# STM32U5G9 register map
File version: 1.3
CPU: CM33 r0p1, little endian, MPU, FPU, 4 interrupt priority bits
Registers are 32-bit, read-write, reset 0x0 unless marked. A register's access mark holds for its fields unless they carry their own. Offsets are from the block's base; [hi:lo] are bit positions; {n}, {i} and the like mark numbered series; 'fields as' and 'values as' point back to an identical list.

## DSI
Base 0x40016C00
Same registers: SEC_DSI 0x50016C00
0x00 DSI_VR ro reset 0x3134312A — DSI Host version register
  [31:0] VERSION — Version of the DSI Host
0x04 DSI_CR — DSI Host control register
  [0] EN — Enable
    0=DSI Host disabled (under reset); 1=DSI Host enabled
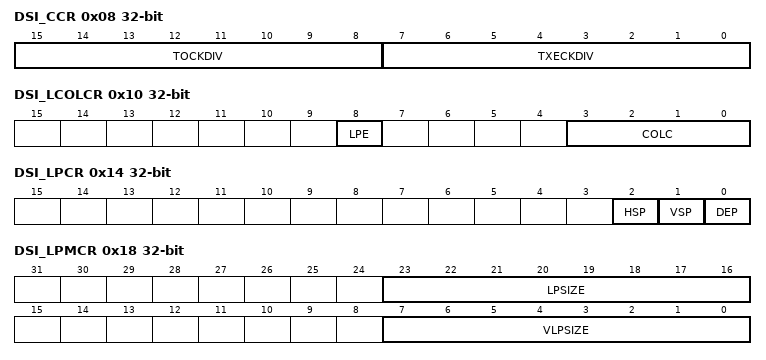
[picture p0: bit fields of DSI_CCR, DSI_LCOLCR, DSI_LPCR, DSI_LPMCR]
0x08 DSI_CCR — DSI Host clock control register
  [15:8] TOCKDIV — Timeout clock division
  [7:0] TXECKDIV — TX escape clock division
0x0C DSI_LVCIDR — DSI Host LTDC VCID register
  [1:0] VCID — Virtual channel ID
0x10 DSI_LCOLCR — DSI Host LTDC color coding register
  [8] LPE — Loosely packet enable
    0=Loosely packet variant disabled; 1=Loosely packet variant enabled
  [3:0] COLC — Color coding
    0=16-bit configuration 1; 1=16-bit configuration 2; 2=16-bit configuration 3; 3=18-bit configuration 1; 4=18-bit configuration 2; 5=24-bit
0x14 DSI_LPCR — DSI Host LTDC polarity configuration register
  [2] HSP — HSYNC polarity
    0=HSYNC pin active high (default); 1=VSYNC pin active low
  [1] VSP — VSYNC polarity
    0=Shutdown pin active high (default); 1=Shutdown pin active low
  [0] DEP — Data enable polarity
    0=Data enable pin active high (default); 1=Data enable pin active low
0x18 DSI_LPMCR — DSI Host low-power mode configuration register
  [23:16] LPSIZE — Largest packet size
  [7:0] VLPSIZE — VACT largest packet size
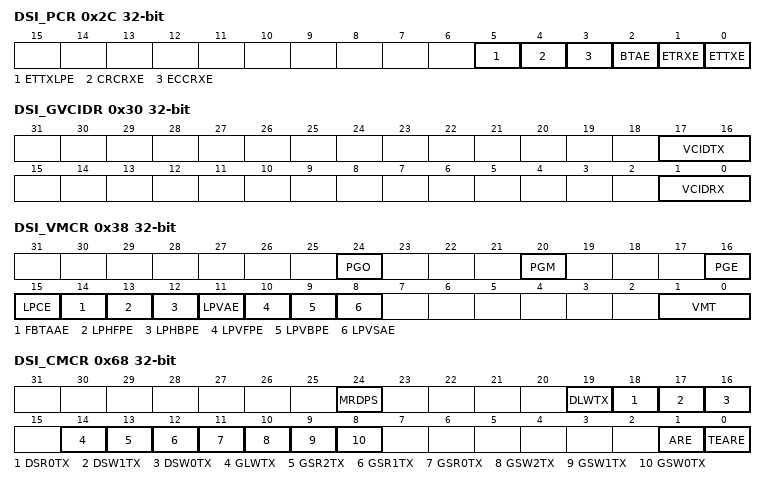
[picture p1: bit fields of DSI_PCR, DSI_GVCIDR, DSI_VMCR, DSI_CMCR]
0x2C DSI_PCR — DSI Host protocol configuration register
  [5] ETTXLPE — EoTp transmission in low-power enable
    0=EoTp transmission in low-power is disabled; 1=EoTp transmission in low-power is enabled
  [4] CRCRXE — CRC reception enable
    0=CRC reception is disabled; 1=CRC reception is enabled
  [3] ECCRXE — ECC reception enable
    0=ECC reception is disabled; 1=ECC reception is enabled
  [2] BTAE — Bus-turn-around enable
    0=Bus-turn-around request is disabled; 1=Bus-turn-around request is enabled
  [1] ETRXE — EoTp reception enable
    0=EoTp reception is disabled; 1=EoTp reception is enabled
  [0] ETTXE — EoTp transmission enable
    0=EoTp transmission is disabled; 1=EoTp transmission is enabled
0x30 DSI_GVCIDR — DSI Host generic VCID register
  [17:16] VCIDTX — Virtual channel ID for transmission
  [1:0] VCIDRX — Virtual channel ID for reception
0x34 DSI_MCR reset 0x1 — DSI Host mode configuration register
  [0] CMDM — Command mode
    0=DSI Host is configured in video mode; 1=DSI Host is configured in command mode
0x38 DSI_VMCR — DSI Host video mode configuration register
  [24] PGO — Pattern generator orientation
    0=Vertical color bars; 1=Horizontal color bars
  [20] PGM — Pattern generator mode
    0=Color bars (horizontal or vertical); 1=BER pattern (vertical only)
  [16] PGE — Pattern generator enable
    0=Pattern generator is disabled; 1=Pattern generator is enabled
  [15] LPCE — Low-power command enable
    0=Command transmission in low-power mode is disabled; 1=Command transmission in low-power mode is enabled
  [14] FBTAAE — Frame bus-turn-around acknowledge enable
    0=Acknowledge response at the end of a frame is disabled; 1=Acknowledge response at the end of a frame is enabled
  [13] LPHFPE — Low-power horizontal front-porch enable
    0=Return to low-power inside the HFP period is disabled; 1=Return to low-power inside the HFP period is enabled
  [12] LPHBPE — Low-power horizontal back-porch enable
    0=Return to low-power inside the HBP period is disabled; 1=Return to low-power inside the HBP period is enabled
  [11] LPVAE — Low-power vertical active enable
    0=Return to low-power inside the VACT is disabled; 1=Return to low-power inside the VACT is enabled
  [10] LPVFPE — Low-power vertical front-porch enable
    0=Return to low-power inside the VFP is disabled; 1=Return to low-power inside the VFP is enabled
  [9] LPVBPE — Low-power vertical back-porch enable
    0=Return to low-power inside the VBP is disabled; 1=Return to low-power inside the VBP is enabled
  [8] LPVSAE — Low-power vertical sync active enable
    0=Return to low-power inside the VSA is disabled; 1=Return to low-power inside the VSA is enabled
  [1:0] VMT — Video mode type
    0=Non-burst with sync pulses; 1=Non-burst with sync events
0x3C DSI_VPCR — DSI Host video packet configuration register
  [13:0] VPSIZE — Video packet size
0x40 DSI_VCCR — DSI Host video chunks configuration register
  [12:0] NUMC — Number of chunks
0x44 DSI_VNPCR — DSI Host video null packet configuration register
  [12:0] NPSIZE — Null packet size
0x48 DSI_VHSACR — DSI Host video HSA configuration register
  [11:0] HSA — Horizontal synchronism active duration
0x4C DSI_VHBPCR — DSI Host video HBP configuration register
  [11:0] HBP — Horizontal back-porch duration
0x50 DSI_VLCR — DSI Host video line configuration register
  [14:0] HLINE — Horizontal line duration
0x54 DSI_VVSACR — DSI Host video VSA configuration register
  [9:0] VSA — Vertical synchronism active duration
0x58 DSI_VVBPCR — DSI Host video VBP configuration register
  [9:0] VBP — Vertical back-porch duration
0x5C DSI_VVFPCR — DSI Host video VFP configuration register
  [9:0] VFP — Vertical front-porch duration
0x60 DSI_VVACR — DSI Host video VA configuration register
  [13:0] VA — Vertical active duration
0x64 DSI_LCCR — DSI Host LTDC command configuration register
  [15:0] CMDSIZE — Command size
0x68 DSI_CMCR — DSI Host command mode configuration register
  [24] MRDPS — Maximum read packet size
    0=High-speed; 1=Low-power
  [19] DLWTX — DCS long write transmission
    0=High-speed; 1=Low-power
  [18] DSR0TX — DCS short read zero parameter transmission
    0=High-speed; 1=Low-power
  [17] DSW1TX — DCS short read one parameter transmission
    0=High-speed; 1=Low-power
  [16] DSW0TX — DCS short write zero parameter transmission
    0=High-speed; 1=Low-power
  [14] GLWTX — Generic long write transmission
    0=High-speed; 1=Low-power
  [13] GSR2TX — Generic short read two parameters transmission
    0=High-speed; 1=Low-power
  [12] GSR1TX — Generic short read one parameters transmission
    0=High-speed; 1=Low-power
  [11] GSR0TX — Generic short read zero parameters transmission
    0=High-speed; 1=Low-power
  [10] GSW2TX — Generic short write two parameters transmission
    0=High-speed; 1=Low-power
  [9] GSW1TX — Generic short write one parameters transmission
    0=High-speed; 1=Low-power
  [8] GSW0TX — Generic short write zero parameters transmission
    0=High-speed; 1=Low-power
  [1] ARE — Acknowledge request enable
    0=Acknowledge request is disabled; 1=Acknowledge request is enabled
  [0] TEARE — Tearing effect acknowledge request enable
    0=Tearing effect acknowledge request is disabled; 1=Tearing effect acknowledge request is enabled
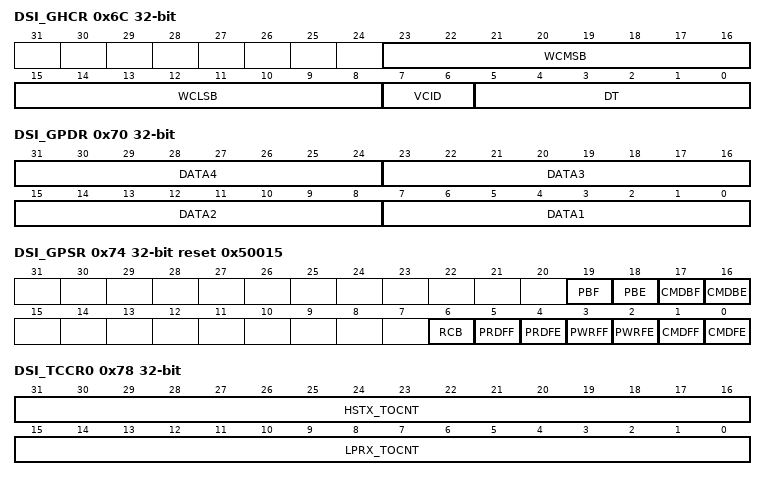
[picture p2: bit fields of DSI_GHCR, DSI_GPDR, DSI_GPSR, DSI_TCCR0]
0x6C DSI_GHCR — DSI Host generic header configuration register
  [23:16] WCMSB — WordCount MSB
  [15:8] WCLSB — WordCount LSB
  [7:6] VCID — Channel
  [5:0] DT — Type
0x70 DSI_GPDR — DSI Host generic payload data register
  [8n-1:8n-8] DATA{n} (n=1..4) — Payload byte {n}
0x74 DSI_GPSR ro reset 0x50015 — DSI Host generic packet status register
  [19] PBF — Payload buffer full
    0=Payload internal buffer not full; 1=Payload internal buffer full
  [18] PBE — Payload buffer empty
    0=Payload internal buffer not empty; 1=Payload internal buffer empty
  [17] CMDBF — Command buffer full
    0=Command internal buffer not full; 1=Command internal buffer full
  [16] CMDBE — Command buffer empty
    values as PBF
  [6] RCB — Read command busy
    0=No read command on going; 1=Read command on going
  [5] PRDFF — Payload read FIFO full
    0=Read payload FIFO not full; 1=Read payload FIFO ful
  [4] PRDFE — Payload read FIFO empty
    0=Read payload FIFO not empty; 1=Read payload FIFO empty
  [3] PWRFF — Payload write FIFO full
    0=Write payload FIFO not full; 1=Write payload FIFO full
  [2] PWRFE — Payload write FIFO empty
    0=Write payload FIFO not empty; 1=Write payload FIFO empty
  [1] CMDFF — Command FIFO full
    0=Write payload FIFO not full; 1=Write payload FIFO full
  [0] CMDFE — Command FIFO empty
    0=Write payload FIFO not empty; 1=Write payload FIFO empty
0x78 DSI_TCCR0 — DSI Host timeout counter configuration register 0
  [31:16] HSTX_TOCNT — High-speed transmission timeout counter
  [15:0] LPRX_TOCNT — Low-power reception timeout counter
0x7C DSI_TCCR1 — DSI Host timeout counter configuration register 1
  [15:0] HSRD_TOCNT — High-speed read timeout counter
0x80 DSI_TCCR2 — DSI Host timeout counter configuration register 2
  [15:0] LPRD_TOCNT — Low-power read timeout counter
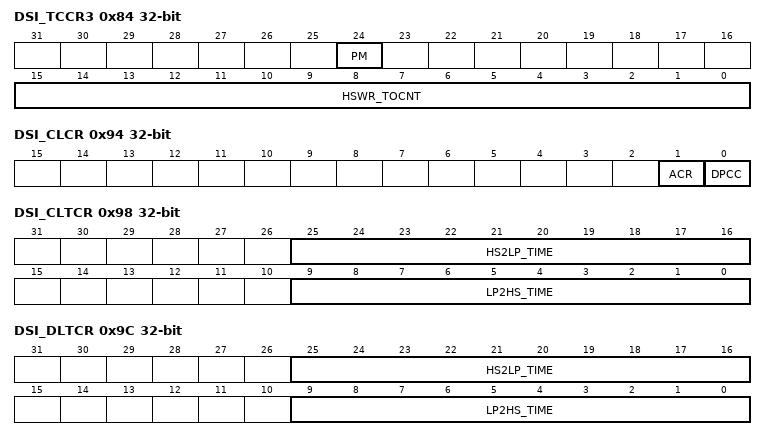
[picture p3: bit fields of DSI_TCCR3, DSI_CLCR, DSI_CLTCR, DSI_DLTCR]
0x84 DSI_TCCR3 — DSI Host timeout counter configuration register 3
  [24] PM — Presp mode
  [15:0] HSWR_TOCNT — High-speed write timeout counter
0x88 DSI_TCCR4 — DSI Host timeout counter configuration register 4
  [15:0] LPWR_TOCNT — Low-power write timeout counter
0x8C DSI_TCCR5 — DSI Host timeout counter configuration register 5
  [15:0] BTA_TOCNT — Bus-turn-around timeout counter
0x94 DSI_CLCR — DSI Host clock lane configuration register
  [1] ACR — Automatic clock lane control
    0=Automatic clock lane control disabled; 1=Automatic clock lane control enabled
  [0] DPCC — D-PHY clock control
    0=Clock lane is in low-power mode; 1=Clock lane runs in high-speed mode
0x98 DSI_CLTCR — DSI Host clock lane timer configuration register
  [25:16] HS2LP_TIME — High-speed to low-power time
  [9:0] LP2HS_TIME — Low-power to high-speed time
0x9C DSI_DLTCR — DSI Host data lane timer configuration register
  fields as DSI_CLTCR
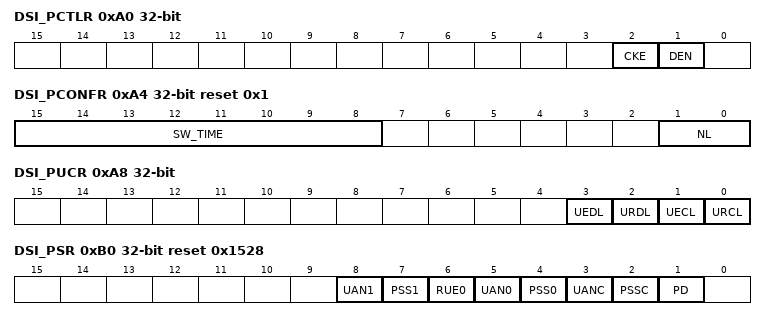
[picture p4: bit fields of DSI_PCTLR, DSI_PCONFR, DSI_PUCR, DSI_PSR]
0xA0 DSI_PCTLR — DSI Host PHY control register
  [2] CKE — Clock enable
    0=D-PHY clock lane module is disabled; 1=D-PHY clock lane module is enabled
  [1] DEN — Digital enable
    0=The digital section of the D-PHY is in the reset state; 1=The digital section of the D-PHY is enabled
0xA4 DSI_PCONFR reset 0x1 — DSI Host PHY configuration register
  [15:8] SW_TIME — Stop wait time
  [1:0] NL — Number of lanes
    0=One data lane (lane 0); 1=Two data lanes (lanes 0 and 1) - Reset value
0xA8 DSI_PUCR — DSI Host PHY ULPS control register
  [3] UEDL — ULPS exit on data lane
    0=No exit request; 1=Exit ULPS mode on all active data lane URDL
  [2] URDL — ULPS request on data lane
    0=No ULPS request; 1=Request ULPS mode on all active data lane UECL
  [1] UECL — ULPS exit on clock lane
    0=No exit request; 1=Exit ULPS mode on clock lane
  [0] URCL — ULPS request on clock lane
    0=No ULPS request; 1=Request ULPS mode on clock lane
0xAC DSI_PTTCR — DSI Host PHY TX triggers configuration register
  [3:0] TX_TRIG — Transmission trigger
0xB0 DSI_PSR ro reset 0x1528 — DSI Host PHY status register
  [8] UAN1 — ULPS active not lane 1
  [7] PSS1 — PHY stop state lane 1
  [6] RUE0 — RX ULPS escape lane 0
  [5] UAN0 — ULPS active not lane 1
  [4] PSS0 — PHY stop state lane 0
  [3] UANC — ULPS active not clock lane
  [2] PSSC — PHY stop state clock lane
  [1] PD — PHY direction
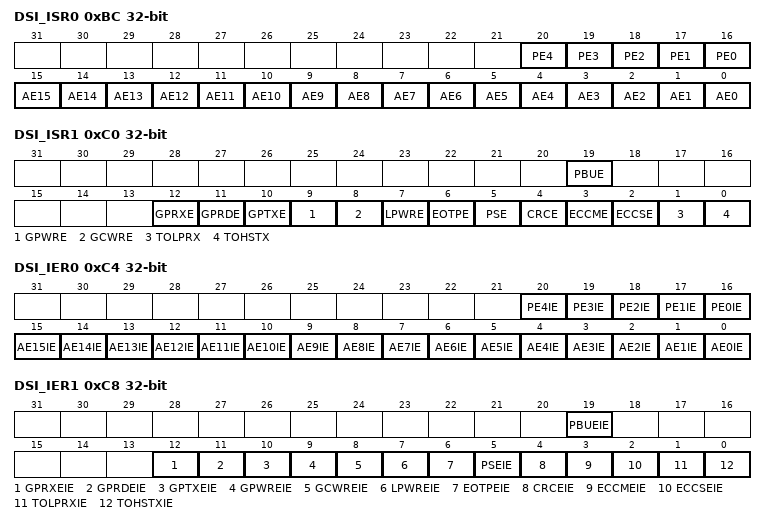
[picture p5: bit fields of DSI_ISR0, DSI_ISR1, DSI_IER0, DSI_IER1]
0xBC DSI_ISR0 ro — DSI Host interrupt and status register 0
  [n+16] PE{n} (n=0..4) — PHY error {n}
  [n] AE{n} (n=0..15) — Acknowledge error {n}
0xC0 DSI_ISR1 ro — DSI Host interrupt and status register 1
  [19] PBUE — Payload buffer underflow error
  [12] GPRXE — Generic payload receive error
  [11] GPRDE — Generic payload read error
  [10] GPTXE — Generic payload transmit error
  [9] GPWRE — Generic payload write error
  [8] GCWRE — Generic command write error
  [7] LPWRE — LTDC payload write error
  [6] EOTPE — EoTp error
  [5] PSE — Packet size error
  [4] CRCE — CRC error
  [3] ECCME — ECC multi-bit error
  [2] ECCSE — ECC single-bit error
  [1] TOLPRX — Timeout low-power reception
  [0] TOHSTX — Timeout high-speed transmission
0xC4 DSI_IER0 — DSI Host interrupt enable register 0
  [n+16] PE{n}IE (n=0..4) — PHY error {n} interrupt enable
    0=Interrupt on PHY error {n} disabled; 1=Interrupt on PHY error {n} enabled
  [n] AE{n}IE (n=11..15) — Acknowledge error {n} interrupt enable
    0=Interrupt on acknowledge error {n} disabled; 1=Interrupt on acknowledge error {n} enabled
  [10] AE10IE — Acknowledge error 10 interrupt enable
    0=Interrupt on acknowledge error 10 disabled; 1=Interrupt on acknowledge error 10 enable
  [n] AE{n}IE (n=0..9) — Acknowledge error {n} interrupt enable
    values as AE11IE
0xC8 DSI_IER1 — DSI Host interrupt enable register 1
  [19] PBUEIE — Payload buffer underflow error interrupt enable
    0=Interrupt on payload buffer underflow error disabled; 1=Interrupt on payload buffer underflow error enabled
  [12] GPRXEIE — Generic payload receive error interrupt enable
    0=Interrupt on generic payload receive error disabled; 1=Interrupt on generic payload receive error enabled
  [11] GPRDEIE — Generic payload read error interrupt enable
    0=Interrupt on generic payload read error disabled; 1=Interrupt on generic payload read error enabled
  [10] GPTXEIE — Generic payload transmit error interrupt enable
    0=Interrupt on generic payload transmit error disabled; 1=Interrupt on generic payload transmit error enabled
  [9] GPWREIE — Generic payload write error interrupt enable
    0=Interrupt on generic payload write error disabled; 1=Interrupt on generic payload write error enabled
  [8] GCWREIE — Generic command write error interrupt enable
    0=Interrupt on generic command write error disabled; 1=Interrupt on generic command write error enabled
  [7] LPWREIE — LTDC payload write error interrupt enable
    0=Interrupt on LTDC payload write error disabled; 1=Interrupt on LTDC payload write error enabled
  [6] EOTPEIE — EoTp error interrupt enable
    0=Interrupt on EoTp error disabled; 1=Interrupt on EoTp error enabled
  [5] PSEIE — Packet size error interrupt enable
    0=Interrupt on packet size error disabled; 1=Interrupt on packet size error enabled
  [4] CRCEIE — CRC error interrupt enable
    0=Interrupt on CRC error disabled; 1=Interrupt on CRC error enabled
  [3] ECCMEIE — ECC multi-bit error interrupt enable
    0=Interrupt on ECC multi-bit error disabled; 1=Interrupt on ECC multi-bit error enabled
  [2] ECCSEIE — ECC single-bit error interrupt enable
    0=Interrupt on ECC single-bit error disabled; 1=Interrupt on ECC single-bit error enabled
  [1] TOLPRXIE — Timeout low-power reception interrupt enable
    0=Interrupt on timeout low-power reception disabled; 1=Interrupt on timeout low-power reception enabled
  [0] TOHSTXIE — Timeout high-speed transmission interrupt enable
    0=Interrupt on timeout high-speed transmission disabled; 1=Interrupt on timeout high-speed transmission enabled
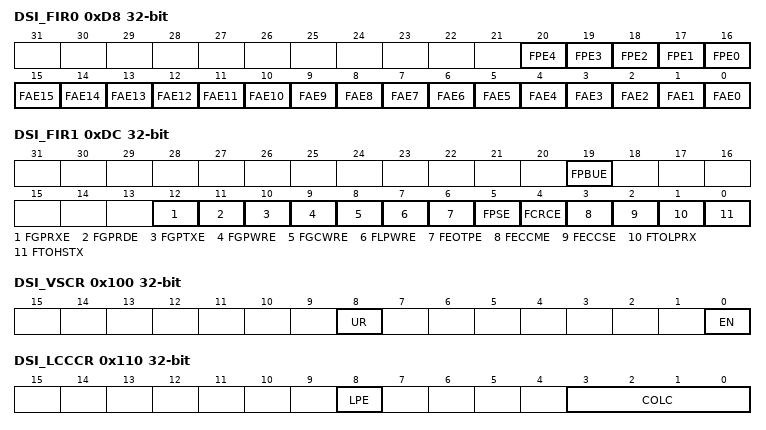
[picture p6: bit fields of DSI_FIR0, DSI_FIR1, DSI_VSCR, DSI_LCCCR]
0xD8 DSI_FIR0 wo — DSI Host force interrupt register 0
  [n+16] FPE{n} (n=0..4) — Force PHY error {n}
  [n] FAE{n} (n=0..15) — Force acknowledge error {n}
0xDC DSI_FIR1 wo — DSI Host force interrupt register 1
  [19] FPBUE — Force payload buffer underflow error
  [12] FGPRXE — Force generic payload receive error
  [11] FGPRDE — Force generic payload read error
  [10] FGPTXE — Force generic payload transmit error
  [9] FGPWRE — Force generic payload write error
  [8] FGCWRE — Force generic command write error
  [7] FLPWRE — Force LTDC payload write error
  [6] FEOTPE — Force EoTp error
  [5] FPSE — Force packet size error
  [4] FCRCE — Force CRC error
  [3] FECCME — Force ECC multi-bit error
  [2] FECCSE — Force ECC single-bit error
  [1] FTOLPRX — Force timeout low-power reception
  [0] FTOHSTX — Force timeout high-speed transmission
0xF4 DSI_DLTRCR — DSI Host data lane timer read configuration register
  [14:0] MRD_TIME — Maximum read time
0x100 DSI_VSCR — DSI Host video shadow control register
  [8] UR — Update register
    0=No update requested; 1=Register update requested
  [0] EN — Enable
    0=Register update is disabled; 1=Register update is enabled
0x10C DSI_LCVCIDR — DSI Host LTDC current VCID register
  [1:0] VCID — Virtual channel ID
0x110 DSI_LCCCR ro — DSI Host LTDC current color coding register
  [8] LPE — Loosely packed enable
    0=Loosely packed variant disabled; 1=Loosely packed variant enabled
  [3:0] COLC — Color coding
    values as DSI_LCOLCR.COLC
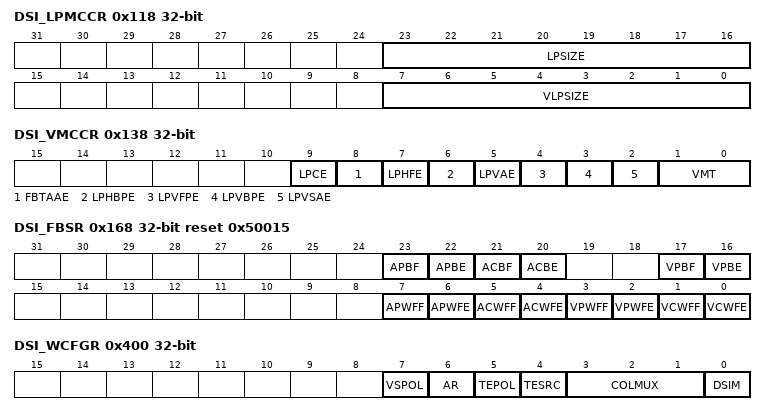
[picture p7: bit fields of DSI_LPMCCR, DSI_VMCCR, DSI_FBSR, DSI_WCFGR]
0x118 DSI_LPMCCR ro — DSI Host low-power mode current configuration register
  fields as DSI_LPMCR
0x138 DSI_VMCCR ro — DSI Host video mode current configuration register
  [9] LPCE — Low-power command enable
    values as DSI_VMCR.LPCE
  [8] FBTAAE — Frame BTA acknowledge enable
    values as DSI_VMCR.FBTAAE
  [7] LPHFE — Low-power horizontal front-porch enable
    values as DSI_VMCR.LPHFPE
  [6] LPHBPE — Low-power horizontal back-porch enable
    values as DSI_VMCR.LPHBPE
  [5] LPVAE — Low-power vertical active enable
    values as DSI_VMCR.LPVAE
  [4] LPVFPE — Low-power vertical front-porch enable
    values as DSI_VMCR.LPVFPE
  [3] LPVBPE — Low-power vertical back-porch enable
    values as DSI_VMCR.LPVBPE
  [2] LPVSAE — Low-power vertical sync time enable
    values as DSI_VMCR.LPVSAE
  [1:0] VMT — Video mode type
    0=Non-burst with sync pulses; 1=Non-burst with sync events
0x13C DSI_VPCCR ro — DSI Host video packet current configuration register
  [13:0] VPSIZE — Video packet size
0x140 DSI_VCCCR ro — DSI Host video chunks current configuration register
  [12:0] NUMC — Number of chunks
0x144 DSI_VNPCCR ro — DSI Host video null packet current configuration register
  [12:0] NPSIZE — Null packet size
0x148 DSI_VHSACCR ro — DSI Host video HSA current configuration register
  [11:0] HSA — Horizontal synchronism active duration
0x14C DSI_VHBPCCR ro — DSI Host video HBP current configuration register
  [11:0] HBP — Horizontal back-porch duration
0x150 DSI_VLCCR ro — DSI Host video line current configuration register
  [14:0] HLINE — Horizontal line duration
0x154 DSI_VVSACCR ro — DSI Host video VSA current configuration register
  [9:0] VSA — Vertical synchronism active duration
0x158 DSI_VVBPCCR ro — DSI Host video VBP current configuration register
  [9:0] VBP — Vertical back-porch duration
0x15C DSI_VVFPCCR ro — DSI Host video VFP current configuration register
  [9:0] VFP — Vertical front-porch duration
0x160 DSI_VVACCR ro — DSI Host video VA current configuration register
  [13:0] VA — Vertical active duration
0x168 DSI_FBSR ro reset 0x50015 — DSI Host FIFO and buffer status register
  [23] APBF — Adapted command mode payload buffer full
    values as DSI_GPSR.PBF
  [22] APBE — Adapted command mode payload buffer empty
    values as DSI_GPSR.PBE
  [21] ACBF — Adapted command mode command buffer full
    values as DSI_GPSR.CMDBF
  [20] ACBE — Adapted command mode command buffer empty
    0=Command internal buffer not empty; 1=Command internal buffer empty
  [17] VPBF — Video mode payload buffer full
    values as DSI_GPSR.PBF
  [16] VPBE — Video mode payload buffer empty
    values as DSI_GPSR.PBE
  [7] APWFF — Adapted command mode payload write FIFO full
    0=Write payload FIFO not full; 1=Write payload FIFO full
  [6] APWFE — Adapted command mode payload write FIFO empty
    0=Write payload FIFO not empty; 1=Write payload FIFO empty
  [5] ACWFF — Adapted command mode command write FIFO full
    0=Write command FIFO not full; 1=Write command FIFO full
  [4] ACWFE — Adapted command mode command write FIFO empty
    0=Write command FIFO not empty; 1=Write command FIFO empty
  [3] VPWFF — Video mode payload write FIFO full
    0=Write payload FIFO not full; 1=Write payload FIFO full
  [2] VPWFE — Video mode payload write FIFO empty
    0=Write payload FIFO not empty; 1=Write payload FIFO empty
  [1] VCWFF — Video mode command write FIFO full
    0=Write command FIFO not full; 1=Write command FIFO full
  [0] VCWFE — Video mode command write FIFO empty
    0=Write command FIFO not empty; 1=Write command FIFO empty
0x400 DSI_WCFGR — DSI Wrapper configuration register
  [7] VSPOL — VSync polarity
    0=LTDC halted on a falling edge; 1=LTDC halted on a rising edge
  [6] AR — Automatic refresh
    0=automatic refresh mode disabled; 1=automatic refresh mode enabled
  [5] TEPOL — TE polarity
    0=rising edge; 1=falling edge
  [4] TESRC — TE source
    0=DSI Link; 1=External pin
  [3:1] COLMUX — Color multiplexing
    values as DSI_LCOLCR.COLC
  [0] DSIM — DSI mode
    0=Video mode; 1=Adapted command mode
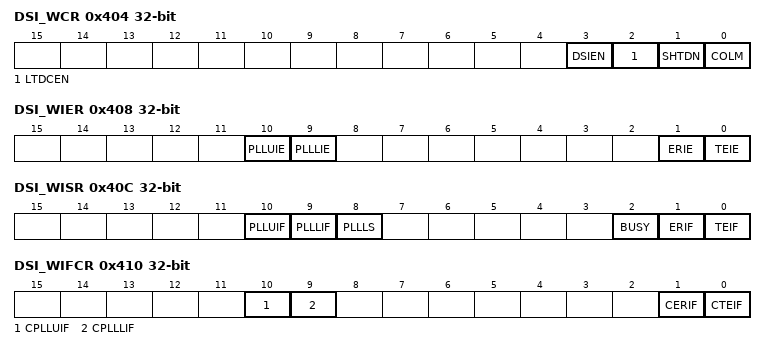
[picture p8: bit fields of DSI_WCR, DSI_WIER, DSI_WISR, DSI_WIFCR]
0x404 DSI_WCR — DSI Wrapper control register
  [3] DSIEN — DSI enable
    0=DSI disabled; 1=DSI enabled
  [2] LTDCEN — LTDC enable
    0=LTDC disabled; 1=LTDC enabled
  [1] SHTDN — Shutdown
    0=display ON; 1=display OFF
  [0] COLM — Color mode
    0=Full color mode; 1=Eight color mode
0x408 DSI_WIER — DSI Wrapper interrupt enable register
  [10] PLLUIE — PLL unlock interrupt enable
    0=PLL unlock interrupt disabled; 1=PLL unlock interrupt enabled
  [9] PLLLIE — PLL lock interrupt enable
    0=PLL lock interrupt disabled; 1=PLL lock interrupt enabled
  [1] ERIE — End of refresh interrupt enable
    0=End of refresh interrupt disabled; 1=End of refresh interrupt enabled
  [0] TEIE — Tearing effect interrupt enable
    0=Tearing effect interrupt disabled; 1=Tearing effect interrupt enabled
0x40C DSI_WISR ro — DSI Wrapper interrupt and status register
  [10] PLLUIF — PLL unlock interrupt flag
    0=No PLL unlock event occurred; 1=PLL unlock event occurred
  [9] PLLLIF — PLL lock interrupt flag
    0=No PLL lock event occurred; 1=PLL lock event occurred
  [8] PLLLS — PLL lock status
    0=PLL is unlocked; 1=PLL is locked
  [2] BUSY — Busy flag
    0=No transfer on going; 1=Transfer on going
  [1] ERIF — End of refresh interrupt flag
    0=No end of refresh event occurred; 1=End of refresh event occurred
  [0] TEIF — Tearing effect interrupt flag
    0=No tearing effect event occurred; 1=Tearing effect event occurred
0x410 DSI_WIFCR wo — DSI Wrapper interrupt flag clear register
  [10] CPLLUIF — Clear PLL unlock interrupt flag
  [9] CPLLLIF — Clear PLL lock interrupt flag
  [1] CERIF — Clear end of refresh interrupt flag
  [0] CTEIF — Clear tearing effect interrupt flag
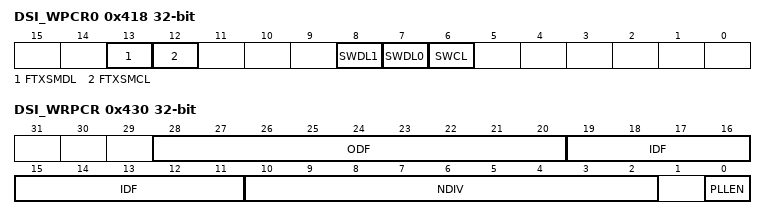
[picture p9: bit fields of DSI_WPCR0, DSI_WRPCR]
0x418 DSI_WPCR0 — DSI Wrapper PHY configuration register 0
  [13] FTXSMDL — Force in TX Stop mode the data lanes
    0=No effect; 1=Force the data lanes in TX Stop mode
  [12] FTXSMCL — Force in TX Stop mode the clock lane
    0=No effect; 1=Force the clock lane in TX Stop mode
  [8] SWDL1 — Swap data lane 1 pins
    0=Regular clock lane pin configuration; 1=Swapped clock lane pin
  [7] SWDL0 — Swap data lane 0 pins
    values as SWDL1
  [6] SWCL — Swap clock lane pins
    values as SWDL1
0x430 DSI_WRPCR — DSI Wrapper regulator and PLL control register
  [28:20] ODF — PLL output division factor
    0=PLL output divided by 1; 1=PLL output divided by 1
  [19:11] IDF — PLL input division factor
    0=PLL input divided by 1; 1=PLL input divided by 1
  [10:2] NDIV — PLL loop division factor
    0=PLL loop divided by 1x2; 1=PLL loop divided by 1x2
  [0] PLLEN — PLL enable
    0=PLL disabled; 1=PLL enabled
0x808 DSI_BCFGR — DSI bias configuration register
  [6] PWRUP — Power-up
    0=Reference bias is powered down; 1=Reference bias is powered up
0xC04 DSI_DPCBCR — DSI D-PHY clock band control register
  [7:3] BC — Band control
    0=80 to 100 MHz; 1=100 to 120 MHz; 2=120 to 160 MHz; 3=160 to 200 MHz; 4=200 to 240 MHz; 5=240 to 320 MHz; 6=320 to 390 MHz; 7=390 to 450 MHz; 8=450 to 510 MHz
0xC34 DSI_DPCSRCR — DSI D-PHY clock skew rate control register
  [7:0] SRC — Slew rate control
    14=80 to 750 Mbit/s
0xC70 DSI_DPDL0BCR — DSI D-PHY data lane 0 band control register
  [4:0] BC — Band control
    values as DSI_DPCBCR.BC
0xCA0 DSI_DPDL0SRCR — DSI D-PHY data lane 0 skew rate control register
  [7:0] SRC — Slew rate control
    14=80 to 750 Mbit/s
0xD08 DSI_DPDL1BCR — DSI D-PHY data lane 1 band control register
  fields as DSI_DPDL0BCR
0xD38 DSI_DPDL1SRCR — DSI D-PHY data lane 1 skew rate control register
  [7:0] SRC — Slew rate control
    14=80 to 750 Mbit/s
